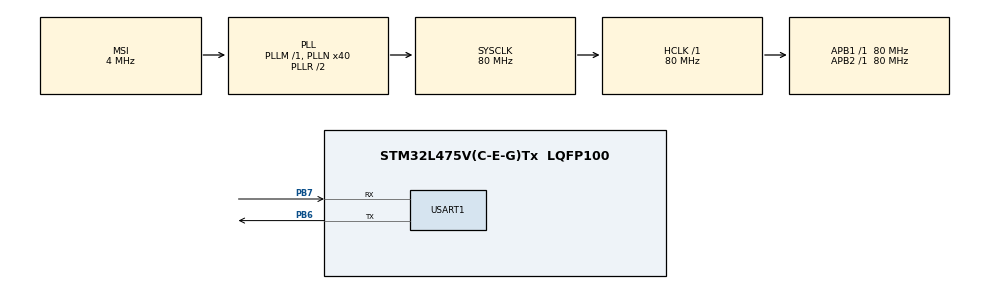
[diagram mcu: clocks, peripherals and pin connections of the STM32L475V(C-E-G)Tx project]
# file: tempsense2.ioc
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ADC1.Channel-0\#ChannelRegularConversion=ADC_CHANNEL_TEMPSENSOR
ADC1.NbrOfConversionFlag=1
ADC1.OffsetNumber-0\#ChannelRegularConversion=ADC_OFFSET_NONE
ADC1.Rank-0\#ChannelRegularConversion=1
ADC1.SamplingTime-0\#ChannelRegularConversion=ADC_SAMPLETIME_2CYCLES_5
ADC1.master=1
Dma.Request0=USART1_RX
Dma.Request1=USART1_TX
Dma.USART1_RX.0.Direction=DMA_PERIPH_TO_MEMORY
Dma.USART1_RX.0.Instance=DMA1_Channel5
Dma.USART1_RX.0.MemDataAlignment=DMA_MDATAALIGN_BYTE
Dma.USART1_RX.0.MemInc=DMA_MINC_ENABLE
Dma.USART1_RX.0.Mode=DMA_NORMAL
Dma.USART1_RX.0.PeriphDataAlignment=DMA_PDATAALIGN_BYTE
Dma.USART1_RX.0.PeriphInc=DMA_PINC_DISABLE
Dma.USART1_RX.0.Priority=DMA_PRIORITY_LOW
Dma.USART1_TX.1.Direction=DMA_MEMORY_TO_PERIPH
Dma.USART1_TX.1.Instance=DMA1_Channel4
Dma.USART1_TX.1.MemDataAlignment=DMA_MDATAALIGN_BYTE
Dma.USART1_TX.1.MemInc=DMA_MINC_ENABLE
Dma.USART1_TX.1.Mode=DMA_NORMAL
Dma.USART1_TX.1.PeriphDataAlignment=DMA_PDATAALIGN_BYTE
Dma.USART1_TX.1.PeriphInc=DMA_PINC_DISABLE
Dma.USART1_TX.1.Priority=DMA_PRIORITY_LOW
Mcu.Family=STM32L4
Mcu.Name=STM32L475V(C-E-G)Tx
Mcu.Package=LQFP100
NVIC.DMA1_Channel4_IRQn=true\:0\:0\:false\:false\:true\:false\:true
NVIC.DMA1_Channel5_IRQn=true\:0\:0\:false\:false\:true\:false\:true
NVIC.PriorityGroup=NVIC_PRIORITYGROUP_4
NVIC.USART1_IRQn=true\:0\:0\:false\:false\:true\:true\:true
PB6.Mode=Asynchronous
PB6.Signal=USART1_TX
PB7.Mode=Asynchronous
PB7.Signal=USART1_RX
ProjectManager.HeapSize=0x200
ProjectManager.StackSize=0x400
ProjectManager.TargetToolchain=MDK-ARM V5
RCC.ADCCLockSelection=RCC_ADCCLKSOURCE_SYSCLK
RCC.ADCFreq_Value=80000000
RCC.AHBFreq_Value=80000000
RCC.APB1Freq_Value=80000000
RCC.APB1TimFreq_Value=80000000
RCC.APB2Freq_Value=80000000
RCC.APB2TimFreq_Value=80000000
RCC.CortexFreq_Value=80000000
RCC.HCLKFreq_Value=80000000
RCC.HSE_VALUE=8000000
RCC.HSI_VALUE=16000000
RCC.LSE_VALUE=32768
RCC.MSI_VALUE=4000000
RCC.PLLN=40
RCC.PLLSAI1N=24
RCC.SYSCLKFreq_VALUE=80000000
RCC.SYSCLKSource=RCC_SYSCLKSOURCE_PLLCLK
RCC.USBFreq_Value=48000000
RCC.VCOOutputFreq_Value=160000000
USART1.VirtualMode-Asynchronous=VM_ASYNC
VP_ADC1_TempSens_Input.Mode=IN-TempSens
board=B-L475E-IOT01A1

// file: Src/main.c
/* USER CODE BEGIN Header */
/**
  ******************************************************************************
  * @file           : main.c
  * @brief          : Main program body
  ******************************************************************************
  * @attention
  *
  * <h2><center>&copy; Copyright (c) 2019 STMicroelectronics.
  * All rights reserved.</center></h2>
  *
  * This software component is licensed by ST under BSD 3-Clause license,
  * the "License"; You may not use this file except in compliance with the
  * License. You may obtain a copy of the License at:
  *                        opensource.org/licenses/BSD-3-Clause
  *
  ******************************************************************************
  */
/* USER CODE END Header */

#include "main.h"
#include "stm32l4xx_hal.h"

#include <stdio.h>
#include <stdlib.h>

ADC_HandleTypeDef hadc1;

UART_HandleTypeDef huart1;
DMA_HandleTypeDef hdma_usart1_rx;
DMA_HandleTypeDef hdma_usart1_tx;

void SystemClock_Config(void);
static void MX_GPIO_Init(void);
static void MX_DMA_Init(void);
static void MX_ADC1_Init(void);
static void MX_USART1_UART_Init(void);

char adc[19] = {'T','e','m','p','e','r','a','t','u','r','e',' ','=',' ','0','0',' ','C','\n'};
char dma[30];
int volatile flag;

int main(void)
{

	uint16_t ADCValue = 0x00;
	flag=0;
  int i=0;

  /* MCU Configuration--------------------------------------------------------*/

  /* Reset of all peripherals, Initializes the Flash interface and the Systick. */
  HAL_Init();

  /* Configure the system clock */
  SystemClock_Config();

  /* Initialize all configured peripherals */
  MX_GPIO_Init();
  MX_DMA_Init();
  MX_ADC1_Init();
  MX_USART1_UART_Init();
  /* USER CODE BEGIN 2 */
	HAL_ADCEx_Calibration_Start(&hadc1, ADC_SINGLE_ENDED);
	HAL_ADC_Start(&hadc1);
  /* USER CODE END 2 */

  /* Infinite loop */
  /* USER CODE BEGIN WHILE */
  while (1)
  {
    //HAL_Delay(100);
		//SysTick_Handler();

		while(i<10){
			if (flag==1){

				HAL_ADC_PollForConversion(&hadc1, 100); //
				ADCValue = HAL_ADC_GetValue(&hadc1);  /* Gets Temp */

				dma[i*3]=((__LL_ADC_CALC_TEMPERATURE(3300, ADCValue, LL_ADC_RESOLUTION_10B))/10)+'0';
				dma[i*3+1]=((__LL_ADC_CALC_TEMPERATURE(3300, ADCValue, LL_ADC_RESOLUTION_10B))%10)+'0';
				dma[i*3+2]='\n';

				/*adc[14]=((__LL_ADC_CALC_TEMPERATURE(3300, ADCValue, LL_ADC_RESOLUTION_10B))/10)+'0';
				adc[15]=((__LL_ADC_CALC_TEMPERATURE(3300, ADCValue, LL_ADC_RESOLUTION_10B))%10)+'0';
				HAL_UART_Transmit_DMA(&huart1, (uint8_t *)&adc[0], 19);*/
				i++;
				flag=0;
			}
		}
		HAL_UART_Transmit_DMA(&huart1, (uint8_t *)&dma[0], 30);
		i=0;
  }
  /* USER CODE END 3 */
}

void SystemClock_Config(void)
{
  RCC_OscInitTypeDef RCC_OscInitStruct = {0};
  RCC_ClkInitTypeDef RCC_ClkInitStruct = {0};
  RCC_PeriphCLKInitTypeDef PeriphClkInit = {0};

  /** Initializes the CPU, AHB and APB busses clocks
  */
  RCC_OscInitStruct.OscillatorType = RCC_OSCILLATORTYPE_MSI;
  RCC_OscInitStruct.MSIState = RCC_MSI_ON;
  RCC_OscInitStruct.MSICalibrationValue = 0;
  RCC_OscInitStruct.MSIClockRange = RCC_MSIRANGE_6;
  RCC_OscInitStruct.PLL.PLLState = RCC_PLL_ON;
  RCC_OscInitStruct.PLL.PLLSource = RCC_PLLSOURCE_MSI;
  RCC_OscInitStruct.PLL.PLLM = 1;
  RCC_OscInitStruct.PLL.PLLN = 40;
  RCC_OscInitStruct.PLL.PLLP = RCC_PLLP_DIV7;
  RCC_OscInitStruct.PLL.PLLQ = RCC_PLLQ_DIV2;
  RCC_OscInitStruct.PLL.PLLR = RCC_PLLR_DIV2;
  if (HAL_RCC_OscConfig(&RCC_OscInitStruct) != HAL_OK)
  {
    Error_Handler();
  }
  /** Initializes the CPU, AHB and APB busses clocks
  */
  RCC_ClkInitStruct.ClockType = RCC_CLOCKTYPE_HCLK|RCC_CLOCKTYPE_SYSCLK
                              |RCC_CLOCKTYPE_PCLK1|RCC_CLOCKTYPE_PCLK2;
  RCC_ClkInitStruct.SYSCLKSource = RCC_SYSCLKSOURCE_PLLCLK;
  RCC_ClkInitStruct.AHBCLKDivider = RCC_SYSCLK_DIV1;
  RCC_ClkInitStruct.APB1CLKDivider = RCC_HCLK_DIV1;
  RCC_ClkInitStruct.APB2CLKDivider = RCC_HCLK_DIV1;

  if (HAL_RCC_ClockConfig(&RCC_ClkInitStruct, FLASH_LATENCY_4) != HAL_OK)
  {
    Error_Handler();
  }
  PeriphClkInit.PeriphClockSelection = RCC_PERIPHCLK_USART1|RCC_PERIPHCLK_ADC;
  PeriphClkInit.Usart1ClockSelection = RCC_USART1CLKSOURCE_PCLK2;
  PeriphClkInit.AdcClockSelection = RCC_ADCCLKSOURCE_SYSCLK;
  if (HAL_RCCEx_PeriphCLKConfig(&PeriphClkInit) != HAL_OK)
  {
    Error_Handler();
  }
  /** Configure the main internal regulator output voltage
  */
  if (HAL_PWREx_ControlVoltageScaling(PWR_REGULATOR_VOLTAGE_SCALE1) != HAL_OK)
  {
    Error_Handler();
  }

	/**Configure the Systick interrupt time
    */
  HAL_SYSTICK_Config(HAL_RCC_GetHCLKFreq()/100); //4M

    /**Configure the Systick
    */
  HAL_SYSTICK_CLKSourceConfig(SYSTICK_CLKSOURCE_HCLK);

  /* SysTick_IRQn interrupt configuration */
  HAL_NVIC_SetPriority(SysTick_IRQn, 0, 0);
}

static void MX_ADC1_Init(void)
{

  ADC_MultiModeTypeDef multimode = {0};
  ADC_ChannelConfTypeDef sConfig = {0};

  /** Common config
  */
  hadc1.Instance = ADC1;
  hadc1.Init.ClockPrescaler = ADC_CLOCK_ASYNC_DIV1;
  hadc1.Init.Resolution = ADC_RESOLUTION_10B;
  hadc1.Init.DataAlign = ADC_DATAALIGN_RIGHT;
  hadc1.Init.ScanConvMode = ADC_SCAN_DISABLE;
  hadc1.Init.EOCSelection = ADC_EOC_SINGLE_CONV;
  hadc1.Init.LowPowerAutoWait = DISABLE;
  hadc1.Init.ContinuousConvMode = ENABLE;
  hadc1.Init.NbrOfConversion = 1;
  hadc1.Init.DiscontinuousConvMode = DISABLE;
  hadc1.Init.ExternalTrigConv = ADC_EXTERNALTRIG_T1_CC1;
  hadc1.Init.ExternalTrigConvEdge = ADC_EXTERNALTRIGCONVEDGE_NONE;
  hadc1.Init.DMAContinuousRequests = DISABLE;
  hadc1.Init.Overrun = ADC_OVR_DATA_OVERWRITTEN;
  hadc1.Init.OversamplingMode = DISABLE;
  if (HAL_ADC_Init(&hadc1) != HAL_OK)
  {
    Error_Handler();
  }
  /** Configure the ADC multi-mode
  */
  multimode.Mode = ADC_MODE_INDEPENDENT;
  if (HAL_ADCEx_MultiModeConfigChannel(&hadc1, &multimode) != HAL_OK)
  {
    Error_Handler();
  }
  /** Configure Regular Channel
  */
  sConfig.Channel = ADC_CHANNEL_TEMPSENSOR;
  sConfig.Rank = ADC_REGULAR_RANK_1;
  sConfig.SamplingTime = ADC_SAMPLETIME_640CYCLES_5;
  sConfig.SingleDiff = ADC_SINGLE_ENDED;
  sConfig.OffsetNumber = ADC_OFFSET_NONE;
  sConfig.Offset = 0;
  if (HAL_ADC_ConfigChannel(&hadc1, &sConfig) != HAL_OK)
  {
    Error_Handler();
  }

}

static void MX_USART1_UART_Init(void)
{

  huart1.Instance = USART1;
  huart1.Init.BaudRate = 115200;
  huart1.Init.WordLength = UART_WORDLENGTH_8B;
  huart1.Init.StopBits = UART_STOPBITS_1;
  huart1.Init.Parity = UART_PARITY_NONE;
  huart1.Init.Mode = UART_MODE_TX_RX;
  huart1.Init.HwFlowCtl = UART_HWCONTROL_NONE;
  huart1.Init.OverSampling = UART_OVERSAMPLING_16;
  huart1.Init.OneBitSampling = UART_ONE_BIT_SAMPLE_DISABLE;
  huart1.AdvancedInit.AdvFeatureInit = UART_ADVFEATURE_NO_INIT;
  if (HAL_UART_Init(&huart1) != HAL_OK)
  {
    Error_Handler();
  }

}

static void MX_DMA_Init(void)
{

  /* DMA controller clock enable */
  __HAL_RCC_DMA1_CLK_ENABLE();

  /* DMA interrupt init */
  /* DMA1_Channel4_IRQn interrupt configuration */
  HAL_NVIC_SetPriority(DMA1_Channel4_IRQn, 0, 0);
  HAL_NVIC_EnableIRQ(DMA1_Channel4_IRQn);
  /* DMA1_Channel5_IRQn interrupt configuration */
  HAL_NVIC_SetPriority(DMA1_Channel5_IRQn, 0, 0);
  HAL_NVIC_EnableIRQ(DMA1_Channel5_IRQn);

}

static void MX_GPIO_Init(void)
{

  /* GPIO Ports Clock Enable */
  __HAL_RCC_GPIOB_CLK_ENABLE();

}

void Error_Handler(void)
{
}

/************************ (C) COPYRIGHT STMicroelectronics *****END OF FILE****/
